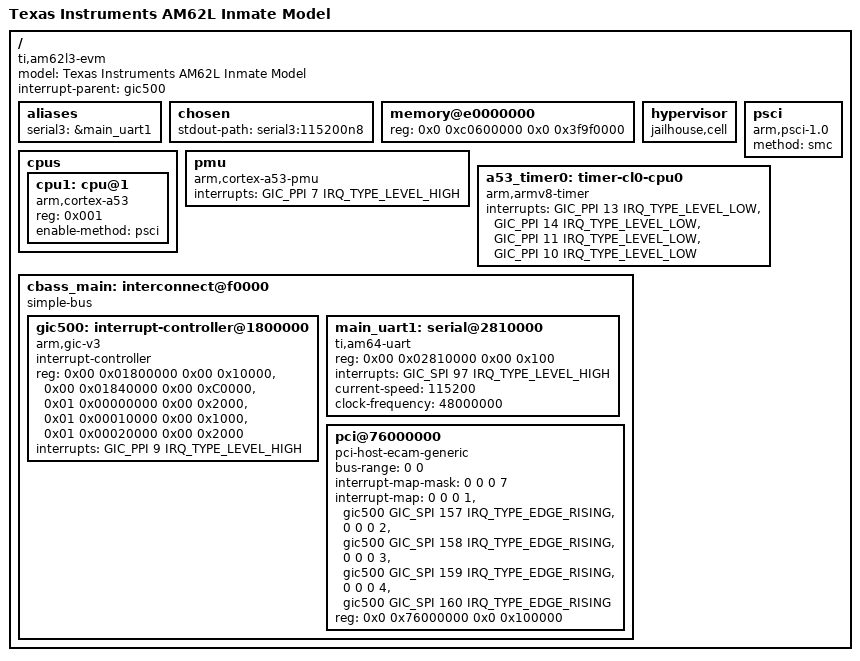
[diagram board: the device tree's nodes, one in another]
/dts-v1/;

#include <dt-bindings/interrupt-controller/arm-gic.h>
#include <dt-bindings/soc/ti,sci_pm_domain.h>

/ {
	model = "Texas Instruments AM62L Inmate Model";
	compatible = "ti,am62l3-evm", "ti,am62l3";
	interrupt-parent = <&gic500>;
	#address-cells = <2>;
	#size-cells = <2>;

	aliases {
		serial3 = &main_uart1;
	};

	chosen {
		stdout-path = "serial3:115200n8";
	};

	memory@e0000000 {
		device_type = "memory";
		reg = <0x0 0xc0600000 0x0 0x3f9f0000>;
	};

	hypervisor {
		compatible = "jailhouse,cell";
	};

	psci: psci {
		compatible = "arm,psci-1.0";
		method = "smc";
	};

	cpus: cpus {
		#address-cells = <1>;
		#size-cells = <0>;

		cpu1: cpu@1 {
			compatible = "arm,cortex-a53";
			reg = <0x001>;
			device_type = "cpu";
			enable-method = "psci";
		};

	};

	pmu: pmu {
		compatible = "arm,cortex-a53-pmu";
		interrupts = <GIC_PPI 7 IRQ_TYPE_LEVEL_HIGH>;
	};

	a53_timer0: timer-cl0-cpu0 {
		compatible = "arm,armv8-timer";
		interrupts = <GIC_PPI 13 IRQ_TYPE_LEVEL_LOW>, /* cntpsirq */
			<GIC_PPI 14 IRQ_TYPE_LEVEL_LOW>, /* cntpnsirq */
			<GIC_PPI 11 IRQ_TYPE_LEVEL_LOW>, /* cntvirq */
			<GIC_PPI 10 IRQ_TYPE_LEVEL_LOW>; /* cnthpirq */
	};

	cbass_main: interconnect@f0000 {
		compatible = "simple-bus";
		#address-cells = <2>;
		#size-cells = <2>;
		ranges;

		gic500: interrupt-controller@1800000 {
			compatible = "arm,gic-v3";
			#interrupt-cells = <3>;
			interrupt-controller;
			reg = <0x00 0x01800000 0x00 0x10000>,	/* GICD */
				<0x00 0x01840000 0x00 0xC0000>,	  /* GICR */
				<0x01 0x00000000 0x00 0x2000>,    /* GICC */
				<0x01 0x00010000 0x00 0x1000>,    /* GICH */
				<0x01 0x00020000 0x00 0x2000>;    /* GICV */
			interrupts = <GIC_PPI 9 IRQ_TYPE_LEVEL_HIGH>;
		};

		main_uart1: serial@2810000 {
			compatible = "ti,am64-uart", "ti,am654-uart";
			reg = <0x00 0x02810000 0x00 0x100>;
			interrupts = <GIC_SPI 97 IRQ_TYPE_LEVEL_HIGH>;
			current-speed = <115200>;
			clock-frequency = <48000000>;
		};

		pci@76000000 {
			compatible = "pci-host-ecam-generic";
			device_type = "pci";
			bus-range = <0 0>;
			#address-cells = <3>;
			#size-cells = <2>;
			#interrupt-cells = <1>;
			interrupt-map-mask = <0 0 0 7>;
			interrupt-map =
			<0 0 0 1 &gic500 GIC_SPI 157 IRQ_TYPE_EDGE_RISING>,
			<0 0 0 2 &gic500 GIC_SPI 158 IRQ_TYPE_EDGE_RISING>,
			<0 0 0 3 &gic500 GIC_SPI 159 IRQ_TYPE_EDGE_RISING>,
			<0 0 0 4 &gic500 GIC_SPI 160 IRQ_TYPE_EDGE_RISING>;
			reg = <0x0 0x76000000 0x0 0x100000>;
			ranges =
			<0x02000000 0x00 0x10000000 0x0 0x10000000 0x00 0x20000>;
		};
	};
};
